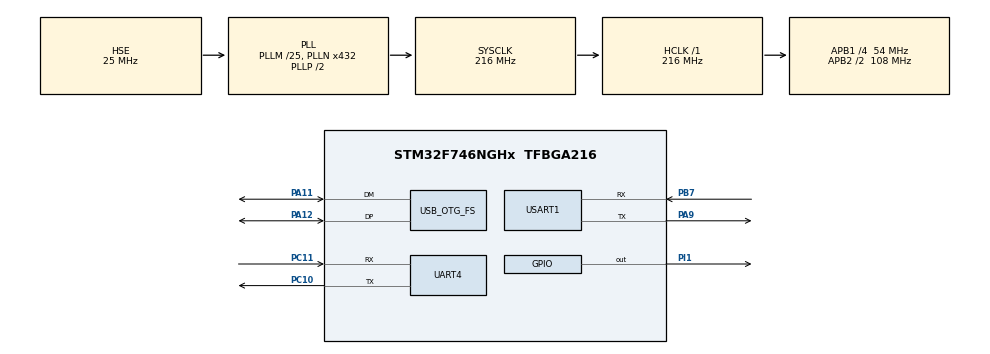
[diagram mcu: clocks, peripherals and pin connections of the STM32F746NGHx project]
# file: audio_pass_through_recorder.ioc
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CORTEX_M7.ART_ACCELERATOR_ENABLE=1
CORTEX_M7.CPU_DCache=Enabled
CORTEX_M7.CPU_ICache=Enabled
CORTEX_M7.PREFETCH_ENABLE=1
FREERTOS.Tasks01=defaultTask,24,128,StartDefaultTask,Default,NULL,Dynamic,NULL,NULL
FREERTOS.configUSE_NEWLIB_REENTRANT=1
Mcu.Family=STM32F7
Mcu.Name=STM32F746NGHx
Mcu.Package=TFBGA216
NVIC.OTG_FS_IRQn=true\:5\:0\:false\:false\:true\:true\:true\:true\:true
NVIC.PriorityGroup=NVIC_PRIORITYGROUP_4
NVIC.RCC_IRQn=true\:5\:0\:false\:false\:true\:true\:true\:false\:true
NVIC.TIM1_UP_TIM10_IRQn=true\:15\:0\:false\:false\:true\:false\:false\:true\:true
NVIC.TimeBase=TIM1_UP_TIM10_IRQn
NVIC.TimeBaseIP=TIM1
PA11.Mode=Device_Only
PA11.Signal=USB_OTG_FS_DM
PA12.Mode=Device_Only
PA12.Signal=USB_OTG_FS_DP
PA13.Mode=Serial_Wire
PA13.Signal=SYS_JTMS-SWDIO
PA14.Mode=Serial_Wire
PA14.Signal=SYS_JTCK-SWCLK
PA9.Mode=Asynchronous
PA9.Signal=USART1_TX
PB7.Mode=Asynchronous
PB7.Signal=USART1_RX
PC10.Mode=Asynchronous
PC10.Signal=UART4_TX
PC11.Mode=Asynchronous
PC11.Signal=UART4_RX
PH0/OSC_IN.Mode=HSE-External-Oscillator
PH0/OSC_IN.Signal=RCC_OSC_IN
PH1/OSC_OUT.Mode=HSE-External-Oscillator
PH1/OSC_OUT.Signal=RCC_OSC_OUT
PI1.Signal=GPIO_Output
ProjectManager.HeapSize=0x200
ProjectManager.StackSize=0x400
ProjectManager.TargetToolchain=STM32CubeIDE
RCC.AHBFreq_Value=216000000
RCC.APB1CLKDivider=RCC_HCLK_DIV4
RCC.APB1Freq_Value=54000000
RCC.APB1TimFreq_Value=108000000
RCC.APB2CLKDivider=RCC_HCLK_DIV2
RCC.APB2Freq_Value=108000000
RCC.APB2TimFreq_Value=216000000
RCC.CortexFreq_Value=216000000
RCC.HCLKFreq_Value=216000000
RCC.HSE_VALUE=25000000
RCC.HSI_VALUE=16000000
RCC.LSE_VALUE=32768
RCC.PLL48CLockSelection=RCC_CLK48SOURCE_PLLSAIP
RCC.PLLI2SN=100
RCC.PLLM=25
RCC.PLLN=432
RCC.PLLQ=9
RCC.PLLSAIN=384
RCC.PLLSAIP=RCC_PLLSAIP_DIV8
RCC.PLLSAIR=5
RCC.PLLSAIRDiv=RCC_PLLSAIDIVR_8
RCC.SDMMCClockSelection=RCC_SDMMC1CLKSOURCE_CLK48
RCC.SYSCLKFreq_VALUE=216000000
RCC.SYSCLKSource=RCC_SYSCLKSOURCE_PLLCLK
RCC.USBFreq_Value=48000000
RCC.VCOOutputFreq_Value=432000000
USART1.VirtualMode-Asynchronous=VM_ASYNC
USB_DEVICE.CLASS_NAME_FS=CDC
USB_DEVICE.VirtualMode-CDC_FS=Cdc
USB_DEVICE.VirtualModeFS=Cdc_FS
USB_OTG_FS.VirtualMode=Device_Only
VP_FREERTOS_VS_CMSIS_V2.Mode=CMSIS_V2
VP_SYS_VS_tim1.Mode=TIM1
VP_USB_DEVICE_VS_USB_DEVICE_CDC_FS.Mode=CDC_FS
board=STM32F746G-DISCO

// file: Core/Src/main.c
/* USER CODE BEGIN Header */
/**
  ******************************************************************************
  * @file           : main.c
  * @brief          : Main program body
  ******************************************************************************
  * @attention
  *
  * Copyright (c) 2024 STMicroelectronics.
  * All rights reserved.
  *
  * This software is licensed under terms that can be found in the LICENSE file
  * in the root directory of this software component.
  * If no LICENSE file comes with this software, it is provided AS-IS.
  *
  ******************************************************************************
  */
/* USER CODE END Header */
#include "main.h"
#include "cmsis_os.h"
#include "usb_device.h"

/* USER CODE BEGIN Includes */

#include "stm32f7xx_mod.h"
#include "kratos_log.h"

/* USER CODE END Includes */

UART_HandleTypeDef huart4;
UART_HandleTypeDef huart1;

/* Definitions for defaultTask */
osThreadId_t defaultTaskHandle;
const osThreadAttr_t defaultTask_attributes = {
  .name = "defaultTask",
  .stack_size = 128 * 4,
  .priority = (osPriority_t) osPriorityNormal,
};

void SystemClock_Config(void);
static void MX_GPIO_Init(void);
static void MX_UART4_Init(void);
static void MX_USART1_UART_Init(void);
void StartDefaultTask(void *argument);

int main(void)
{

  /* Enable the CPU Cache */

  /* Enable I-Cache---------------------------------------------------------*/
  SCB_EnableICache();

  /* Enable D-Cache---------------------------------------------------------*/
  SCB_EnableDCache();

  /* MCU Configuration--------------------------------------------------------*/

  /* Reset of all peripherals, Initializes the Flash interface and the Systick. */
  HAL_Init();

  /* Configure the system clock */
  SystemClock_Config();

  /* Initialize all configured peripherals */
  MX_GPIO_Init();
  MX_UART4_Init();
  MX_USART1_UART_Init();
  /* USER CODE BEGIN 2 */

  log_set_uart(&huart1);

  /* USER CODE END 2 */

  /* Init scheduler */
  osKernelInitialize();

  /* Create the thread(s) */
  /* creation of defaultTask */
  defaultTaskHandle = osThreadNew(StartDefaultTask, NULL, &defaultTask_attributes);

  /* Start scheduler */
  osKernelStart();

  /* We should never get here as control is now taken by the scheduler */

  /* Infinite loop */
  while (1)
  {

  }
}

void SystemClock_Config(void)
{
  RCC_OscInitTypeDef RCC_OscInitStruct = {0};
  RCC_ClkInitTypeDef RCC_ClkInitStruct = {0};

  /** Configure the main internal regulator output voltage
  */
  __HAL_RCC_PWR_CLK_ENABLE();
  __HAL_PWR_VOLTAGESCALING_CONFIG(PWR_REGULATOR_VOLTAGE_SCALE1);

  /** Initializes the RCC Oscillators according to the specified parameters
  * in the RCC_OscInitTypeDef structure.
  */
  RCC_OscInitStruct.OscillatorType = RCC_OSCILLATORTYPE_HSE;
  RCC_OscInitStruct.HSEState = RCC_HSE_ON;
  RCC_OscInitStruct.PLL.PLLState = RCC_PLL_ON;
  RCC_OscInitStruct.PLL.PLLSource = RCC_PLLSOURCE_HSE;
  RCC_OscInitStruct.PLL.PLLM = 25;
  RCC_OscInitStruct.PLL.PLLN = 432;
  RCC_OscInitStruct.PLL.PLLP = RCC_PLLP_DIV2;
  RCC_OscInitStruct.PLL.PLLQ = 9;
  if (HAL_RCC_OscConfig(&RCC_OscInitStruct) != HAL_OK)
  {
    Error_Handler();
  }

  /** Activate the Over-Drive mode
  */
  if (HAL_PWREx_EnableOverDrive() != HAL_OK)
  {
    Error_Handler();
  }

  /** Initializes the CPU, AHB and APB buses clocks
  */
  RCC_ClkInitStruct.ClockType = RCC_CLOCKTYPE_HCLK|RCC_CLOCKTYPE_SYSCLK
                              |RCC_CLOCKTYPE_PCLK1|RCC_CLOCKTYPE_PCLK2;
  RCC_ClkInitStruct.SYSCLKSource = RCC_SYSCLKSOURCE_PLLCLK;
  RCC_ClkInitStruct.AHBCLKDivider = RCC_SYSCLK_DIV1;
  RCC_ClkInitStruct.APB1CLKDivider = RCC_HCLK_DIV4;
  RCC_ClkInitStruct.APB2CLKDivider = RCC_HCLK_DIV2;

  if (HAL_RCC_ClockConfig(&RCC_ClkInitStruct, FLASH_LATENCY_7) != HAL_OK)
  {
    Error_Handler();
  }
}

static void MX_UART4_Init(void)
{

  huart4.Instance = UART4;
  huart4.Init.BaudRate = 115200;
  huart4.Init.WordLength = UART_WORDLENGTH_8B;
  huart4.Init.StopBits = UART_STOPBITS_1;
  huart4.Init.Parity = UART_PARITY_NONE;
  huart4.Init.Mode = UART_MODE_TX_RX;
  huart4.Init.HwFlowCtl = UART_HWCONTROL_NONE;
  huart4.Init.OverSampling = UART_OVERSAMPLING_16;
  huart4.Init.OneBitSampling = UART_ONE_BIT_SAMPLE_DISABLE;
  huart4.AdvancedInit.AdvFeatureInit = UART_ADVFEATURE_NO_INIT;
  if (HAL_UART_Init(&huart4) != HAL_OK)
  {
    Error_Handler();
  }

}

static void MX_USART1_UART_Init(void)
{

  huart1.Instance = USART1;
  huart1.Init.BaudRate = 115200;
  huart1.Init.WordLength = UART_WORDLENGTH_8B;
  huart1.Init.StopBits = UART_STOPBITS_1;
  huart1.Init.Parity = UART_PARITY_NONE;
  huart1.Init.Mode = UART_MODE_TX_RX;
  huart1.Init.HwFlowCtl = UART_HWCONTROL_NONE;
  huart1.Init.OverSampling = UART_OVERSAMPLING_16;
  huart1.Init.OneBitSampling = UART_ONE_BIT_SAMPLE_DISABLE;
  huart1.AdvancedInit.AdvFeatureInit = UART_ADVFEATURE_NO_INIT;
  if (HAL_UART_Init(&huart1) != HAL_OK)
  {
    Error_Handler();
  }

}

static void MX_GPIO_Init(void)
{
  GPIO_InitTypeDef GPIO_InitStruct = {0};

  /* GPIO Ports Clock Enable */
  __HAL_RCC_GPIOA_CLK_ENABLE();
  __HAL_RCC_GPIOB_CLK_ENABLE();
  __HAL_RCC_GPIOC_CLK_ENABLE();
  __HAL_RCC_GPIOI_CLK_ENABLE();
  __HAL_RCC_GPIOH_CLK_ENABLE();

  /*Configure GPIO pin Output Level */
  HAL_GPIO_WritePin(GPIOI, GPIO_PIN_1, GPIO_PIN_RESET);

  /*Configure GPIO pin : PI1 */
  GPIO_InitStruct.Pin = GPIO_PIN_1;
  GPIO_InitStruct.Mode = GPIO_MODE_OUTPUT_PP;
  GPIO_InitStruct.Pull = GPIO_NOPULL;
  GPIO_InitStruct.Speed = GPIO_SPEED_FREQ_LOW;
  HAL_GPIO_Init(GPIOI, &GPIO_InitStruct);

}

void StartDefaultTask(void *argument)
{
  /* init code for USB_DEVICE */
  MX_USB_DEVICE_Init();
  /* USER CODE BEGIN 5 */
  /* Infinite loop */
  mod_toggle_led1();

  printf("Starting testing code...\n");

  for(;;)
  {
    osDelay(5000);
    mod_send_usb_test_data();
    mod_send_uart_test_logs();
  }
  /* USER CODE END 5 */
}

void HAL_TIM_PeriodElapsedCallback(TIM_HandleTypeDef *htim)
{
  if (htim->Instance == TIM1) {
    HAL_IncTick();
  }
}

void Error_Handler(void)
{
  __disable_irq();
  while (1)
  {
  }
}
